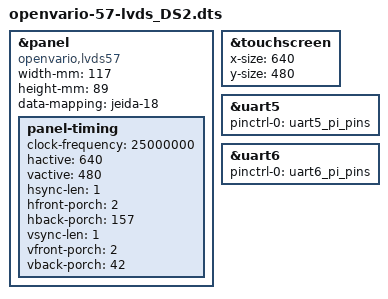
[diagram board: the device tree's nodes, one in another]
#include "openvario-common.dts"

&panel {
    compatible = "openvario,lvds57", "panel-lvds";
    width-mm = <117>;
    height-mm = <89>;
    data-mapping = "jeida-18";

    panel-timing {
        /* 640x480 @60Hz */
        clock-frequency = <25000000>;
        hactive = <640>;
        vactive = <480>;
        hsync-len = <1>;
        hfront-porch = <2>;
        hback-porch = <157>;
        vsync-len = <1>;
        vfront-porch = <2>;
        vback-porch = <42>;
    };
};

&touchscreen {
    x-size = <640>;
    y-size = <480>;
};

// UART5 on Schematic
&uart5 {
    pinctrl-0 = <&uart5_pi_pins>;
};

// UART6 on Schematic
&uart6 {
    pinctrl-names = "default";
    pinctrl-0 = <&uart6_pi_pins>;
    status = "okay";
};
